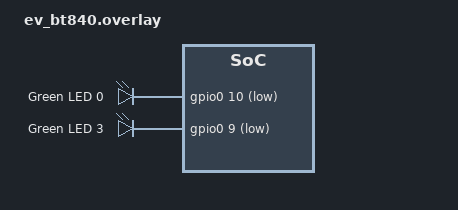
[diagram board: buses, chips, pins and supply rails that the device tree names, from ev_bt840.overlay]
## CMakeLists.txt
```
cmake_minimum_required(VERSION 3.20.0)

add_compile_options(-fdiagnostics-color=always)
add_compile_options(-Wall)
#add_compile_options(-Werror)

find_package(Zephyr REQUIRED HINTS $ENV{ZEPHYR_BASE})
project(radio_rx)

target_sources(app PRIVATE src/main.c src/rx_uart.c src/rx_radio.c src/common/radio.c)
```

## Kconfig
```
source "Kconfig.zephyr"

menu "Serial Radio: Receiver"

config RADIO_RX_APP_LOG_LEVEL
	int "Log level for the radio_rx"
	default 4

endmenu
```

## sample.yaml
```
sample:
  description: Serial Radio Receiver
  name: radio_rx
common:
    tags: introduction
    integration_platforms:
      - native_posix
    harness: console
    harness_config:
      type: one_line
      regex:
        - "Hello World! (.*)"
tests:
  sample.basic.helloworld:
    tags: introduction
```

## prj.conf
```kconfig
CONFIG_DEBUG_THREAD_INFO=n
CONFIG_DEBUG_OPTIMIZATIONS=n

CONFIG_GPIO=y
CONFIG_NFCT_PINS_AS_GPIOS=y

CONFIG_LOG=n
CONFIG_CONSOLE=n

CONFIG_SERIAL=y
CONFIG_UART_ASYNC_API=y
CONFIG_UART_0_NRF_HW_ASYNC=y
# TIMER2 is apparently used by the ESB library.
CONFIG_UART_0_NRF_HW_ASYNC_TIMER=1
CONFIG_UART_1_NRF_HW_ASYNC=y
# TIMER2 is apparently used by the ESB library.
CONFIG_UART_1_NRF_HW_ASYNC_TIMER=3

CONFIG_ESB=y
CONFIG_ESB_TX_FIFO_SIZE=1
CONFIG_ESB_RX_FIFO_SIZE=2
CONFIG_ESB_MAX_PAYLOAD_LENGTH=252

CONFIG_RING_BUFFER=y

CONFIG_MPSL=y
CONFIG_MPSL_FEM_ONLY=y
```

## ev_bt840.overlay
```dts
/ {
	leds {
		compatible = "gpio-leds";
		led0: led_0 {
			gpios = <&gpio0 10 GPIO_ACTIVE_LOW>;
			label = "Green LED 0";
		};
		led3: led_3 {
			gpios = <&gpio0 9 GPIO_ACTIVE_LOW>;
			label = "Green LED 3";
		};
	};
};
```

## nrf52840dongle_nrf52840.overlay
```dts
// To get started, press Ctrl+Space to bring up the completion menu and view the available nodes.

// You can also use the buttons in the sidebar to perform actions on nodes.
// Actions currently available include:

// * Enabling / disabling the node
// * Adding the bus to a bus
// * Removing the node
// * Connecting ADC channels

// For more help, browse the DeviceTree documentation at https://docs.zephyrproject.org/latest/guides/dts/index.html
// You can also visit the nRF DeviceTree extension documentation at https://nrfconnect.github.io/vscode-nrf-connect/devicetree/nrfdevicetree.html

&pinctrl {
	uart0_default: uart0_default {
		group1 {
			psels = <NRF_PSEL(UART_TX, 0, 20)>;
		};
		group2 {
			psels = <NRF_PSEL(UART_RX, 0, 22)>;
			bias-pull-up;
		};
	};

	uart0_sleep: uart0_sleep {
		group1 {
			psels = <NRF_PSEL(UART_TX, 0, 20)>,
				<NRF_PSEL(UART_RX, 0, 22)>;
			low-power-enable;
		};
	};

	uart1_default: uart1_default {
		group1 {
			psels = <NRF_PSEL(UART_TX, 0, 15)>;
		};
		group2 {
			psels = <NRF_PSEL(UART_RX, 0, 17)>;
			bias-pull-up;
		};
	};

	uart1_sleep: uart1_sleep {
		group1 {
			psels = <NRF_PSEL(UART_TX, 0, 15)>,
				<NRF_PSEL(UART_RX, 0, 17)>;
			low-power-enable;
		};
	};
};

&uart1 {
	compatible = "nordic,nrf-uarte";
	status = "okay";
	current-speed = <115200>;
	pinctrl-0 = <&uart1_default>;
	pinctrl-1 = <&uart1_sleep>;
	pinctrl-names = "default", "sleep";
};
```

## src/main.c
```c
#include <esb.h>
#include <zephyr/drivers/uart.h>
#include <zephyr/logging/log.h>
#include <zephyr/sys/ring_buffer.h>

LOG_MODULE_REGISTER(radio_tx, CONFIG_RADIO_TX_APP_LOG_LEVEL);

#include "common/leds.h"
#include "common/radio.h"
#include "rx_radio.h"
#include "rx_uart.h"

// Application defines
#define NUM_CHANNEL RADIO_NUM_PIPES
#define PIPE_BUF_LEN 512

// Thread defines
#define THREAD_NUM 3
#define THREAD_STACK_SIZE 512
#define THREAD_RADIO_PRIORITY 10
#define THREAD_UART_PRIORITY 20
#define THREAD_MAIN_PRIORITY 30

typedef struct {
  const char *name;
  struct k_thread *thread_data;
  k_thread_stack_t *stack;
  size_t stack_size;
  k_thread_entry_t entry;
  void *entry_arg1;
  void *entry_arg2;
  void *entry_arg3;
  int priority;
  uint32_t options;
  k_timeout_t delay;
} ThreadConfig;

// Static state for threads and application.
static uint8_t g_pipe_bufs[NUM_CHANNEL][PIPE_BUF_LEN];
static LitePipe g_pipes[NUM_CHANNEL];

static UartTxState g_uart_states[NUM_CHANNEL];

K_THREAD_STACK_ARRAY_DEFINE(g_thread_stacks, THREAD_NUM, THREAD_STACK_SIZE);
static struct k_thread g_thread_data[THREAD_NUM];

static void InitPipes(void) {
  for (int i = 0; i < NUM_CHANNEL; ++i) {
    LitePipeInit(&g_pipes[i], g_pipe_bufs[i], sizeof(g_pipe_bufs[i]));
  }
}

void main(void) {
  LOG_INF("Starting RX radio...");

  if (SetupLeds() < 0) {
    return;
  };

  InitPipes();

  const UartTxConfig uart_configs[NUM_CHANNEL] = {
      {
          .uart = DEVICE_DT_GET(DT_NODELABEL(uart0)),
          .baud = 921600,
          .pipe = &g_pipes[0],
      },
      {
          .uart = DEVICE_DT_GET(DT_NODELABEL(uart1)),
          .baud = 921600,
          .pipe = &g_pipes[1],
      },
  };

  const RadioRxConfig radio_config = {.pipes = {&g_pipes[0], &g_pipes[1]}};

  k_tid_t threads[THREAD_NUM];
  const ThreadConfig thread_configs[THREAD_NUM] = {
      {
          .name = "RadioRx",
          .thread_data = &g_thread_data[0],
          .stack = g_thread_stacks[0],
          .stack_size = K_THREAD_STACK_SIZEOF(g_thread_stacks[0]),
          .entry = (k_thread_entry_t)RadioRxThread,
          .entry_arg1 = (void *)&radio_config,
          .entry_arg2 = NULL,
          .entry_arg3 = NULL,
          .priority = THREAD_RADIO_PRIORITY,
          .options = 0,
          .delay = K_NO_WAIT,
      },
      {
          .name = "Uart0",
          .thread_data = &g_thread_data[1],
          .stack = g_thread_stacks[1],
          .stack_size = K_THREAD_STACK_SIZEOF(g_thread_stacks[1]),
          .entry = (k_thread_entry_t)UartTxThread,
          .entry_arg1 = (void *)&uart_configs[0],
          .entry_arg2 = &g_uart_states[0],
          .entry_arg3 = NULL,
          .priority = THREAD_UART_PRIORITY + 0,
          .options = 0,
          .delay = K_NO_WAIT,
      },
      {
          .name = "Uart1",
          .thread_data = &g_thread_data[2],
          .stack = g_thread_stacks[2],
          .stack_size = K_THREAD_STACK_SIZEOF(g_thread_stacks[2]),
          .entry = (k_thread_entry_t)UartTxThread,
          .entry_arg1 = (void *)&uart_configs[1],
          .entry_arg2 = &g_uart_states[1],
          .entry_arg3 = NULL,
          .priority = THREAD_UART_PRIORITY + 1,
          .options = 0,
          .delay = K_NO_WAIT,
      },
  };

  for (int i = 0; i < THREAD_NUM; ++i) {
    const ThreadConfig *const c = &thread_configs[i];
    threads[i] = k_thread_create(c->thread_data, c->stack, c->stack_size, c->entry, c->entry_arg1,
                                 c->entry_arg2, c->entry_arg3, c->priority, c->options, c->delay);
    k_thread_name_set(threads[i], c->name);
  }

  // Set priority to background allowing other threads to start.
  k_thread_priority_set(k_current_get(), THREAD_MAIN_PRIORITY);

  bool running_led = false;
  while (true) {
    k_msleep(500);

    // Toggle running LED.
    running_led = !running_led;
    SetLed(LED_RUNNING, running_led);

    // Set error LED based on state of threads.
    bool error_status = false;
    error_status = error_status || RadioRxGetErrorStatus();
    error_status = error_status || UartTxGetErrorStatus(&g_uart_states[0]);
    error_status = error_status || UartTxGetErrorStatus(&g_uart_states[1]);

    SetLed(LED_ERROR, error_status);

    // If any threads exit, toggle error LED indefinitely.
    for (int i = 0; i < THREAD_NUM; ++i) {
      int ret = k_thread_join(thread_configs[i].thread_data, K_NO_WAIT);
      while (ret == 0) {
        SetLed(LED_ERROR, true);
        k_msleep(500);
        SetLed(LED_ERROR, false);
        k_msleep(500);
      }
    }
  }
}
```

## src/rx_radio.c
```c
#include "rx_radio.h"

#include <string.h>

#include <esb.h>
#include <zephyr/kernel.h>
#include <zephyr/logging/log.h>
#include <zephyr/sys/ring_buffer.h>

LOG_MODULE_REGISTER(rx_radio, CONFIG_LOG_LEVEL_DEFAULT);

#include "common/leds.h"
#include "common/lite_pipe.h"
#include "common/radio.h"

typedef struct {
  struct {
    atomic_t pipe_overflow[RADIO_NUM_PIPES];
    atomic_t other;
  } errors;
  atomic_t rx_packets;
  atomic_t rx_bytes[RADIO_NUM_PIPES];
} RadioStats;

typedef struct {
  struct k_sem rx_sem;
  struct esb_payload rx_payload;
  RadioStats stats;
} RadioRxState;

static RadioRxState g_radio_state;

static void EsbHandler(const struct esb_evt *event) {
  switch (event->evt_id) {
    case ESB_EVENT_RX_RECEIVED:
      atomic_inc(&g_radio_state.stats.rx_packets);
      SetLed(LED_RADIO_STATUS, true);
      k_sem_give(&g_radio_state.rx_sem);
      break;
    case ESB_EVENT_TX_SUCCESS:
    case ESB_EVENT_TX_FAILED:
      atomic_inc(&g_radio_state.stats.errors.other);
      break;
  }
}

static int RadioInit(void) {
  k_sem_init(&g_radio_state.rx_sem, 0, 1);
  memset(&g_radio_state.stats, 0, sizeof(g_radio_state.stats));

  if (SetupEsb(ESB_MODE_PRX, EsbHandler) < 0) return -1;

  if (esb_start_rx() < 0) {
    LOG_ERR("Could not start ESB receiving.");
    return -1;
  }

  return 0;
}

bool RadioRxGetErrorStatus(void) {
  bool status = false;

  for (int i = 0; i < RADIO_NUM_PIPES; ++i) {
    status = status || atomic_get(&g_radio_state.stats.errors.pipe_overflow[i]); 
  }

  status = status || atomic_get(&g_radio_state.stats.errors.other);

  return status;
}

void RadioRxThread(const RadioRxConfig *config, void *arg2, void *arg3) {
  if (RadioInit() < 0) return;

  while (true) {
    // Wait for RX data from radio.
    if (k_sem_take(&g_radio_state.rx_sem, K_FOREVER) < 0) {
      atomic_inc(&g_radio_state.stats.errors.other);
      continue;
    }

    // Continually move data from RX FIFO to appropriate ring buffer.
    while (true) {
      int ret = esb_read_rx_payload(&g_radio_state.rx_payload);
      if (ret < 0) {
        if (ret != -ENODATA) {
          atomic_inc(&g_radio_state.stats.errors.other);
        }
        break;
      }

      // Ignore if pipe is out of bounds.
      const uint8_t pipe_num = g_radio_state.rx_payload.pipe;
      if (pipe_num >= RADIO_NUM_PIPES) {
        atomic_inc(&g_radio_state.stats.errors.other);
        continue;
      }

      LitePipe *const pipe = config->pipes[pipe_num];
      uint8_t *const data = g_radio_state.rx_payload.data;
      const size_t len = g_radio_state.rx_payload.length;

      // Flush pipe if not enough room to write RX payload.
      if (LitePipePutAvailable(pipe) < len) {
        atomic_inc(&g_radio_state.stats.errors.pipe_overflow[pipe_num]);

        if (LitePipeFlush(pipe, K_FOREVER) < 0) {
          atomic_inc(&g_radio_state.stats.errors.other);
        }
      }

      // Write RX payload to pipe.
      const size_t bytes_written = LitePipePut(pipe, data, len);
      if (bytes_written != len) {
        atomic_inc(&g_radio_state.stats.errors.other);
      }

      atomic_add(&g_radio_state.stats.rx_bytes[pipe_num], bytes_written);
    }
  }
}
```

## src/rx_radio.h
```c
#pragma once

#include "common/lite_pipe.h"
#include "common/radio.h"

typedef struct {
  LitePipe *pipes[RADIO_NUM_PIPES];
} RadioRxConfig;

void RadioRxThread(const RadioRxConfig *config, void *arg2, void *arg3);
bool RadioRxGetErrorStatus(void);
```

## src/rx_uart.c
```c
#include "rx_uart.h"

#include <string.h>

#include <zephyr/drivers/uart.h>
#include <zephyr/logging/log.h>
#include <zephyr/kernel.h>

LOG_MODULE_REGISTER(rx_uart, CONFIG_LOG_LEVEL_DEFAULT);

#include "common/leds.h"
#include "common/lite_pipe.h"

static void UartCallback(const struct device *uart, struct uart_event *event, UartTxState *state) {
  switch (event->type) {
    case UART_TX_ABORTED:
      atomic_inc(&state->stats.errors.other);
    case UART_TX_DONE:
      atomic_add(&state->stats.tx_bytes, event->data.tx.len);

      SetLed(LED_RADIO_STATUS, false);

      if (k_sem_count_get(&state->tx_done_sem) != 0) {
        atomic_inc(&state->stats.errors.tx_multiple_callbacks);
      }
      k_sem_give(&state->tx_done_sem);
      break;
    case UART_RX_BUF_REQUEST:
    case UART_RX_RDY:
    case UART_RX_DISABLED:
    case UART_RX_STOPPED:
    case UART_RX_BUF_RELEASED:
      atomic_inc(&state->stats.errors.other);
      break;
  }
}

static int UartInit(const UartTxConfig *config, UartTxState *state) {
  int ret;
  if ((ret = k_sem_init(&state->tx_done_sem, 1, 1)) < 0) return ret;
  state->buf_write_index = 0;
  memset(&state->stats, 0, sizeof(state->stats));

  const struct uart_config uart_config = {
      .baudrate = config->baud,
      .parity = UART_CFG_PARITY_NONE,
      .stop_bits = UART_CFG_STOP_BITS_1,
      .data_bits = UART_CFG_DATA_BITS_8,
      .flow_ctrl = UART_CFG_FLOW_CTRL_NONE,
  };

  if (!device_is_ready(config->uart)) {
    LOG_ERR("Could not get uart.");
    return -1;
  }

  if (uart_configure(config->uart, &uart_config) < 0) {
    LOG_ERR("Could not configure uart.");
    return -1;
  }

  if (uart_callback_set(config->uart, (uart_callback_t)UartCallback, state) < 0) {
    LOG_ERR("Could not set uart callback.");
    return -1;
  }

  return 0;
}

bool UartTxGetErrorStatus(const UartTxState *state) {
  bool status = false;
  status = status || atomic_get(&state->stats.errors.tx_multiple_callbacks);
  status = status || atomic_get(&state->stats.errors.other);

  return status;
}

void UartTxThread(const UartTxConfig *config, UartTxState *state, void *arg3) {
  if (UartInit(config, state) < 0) return;

  while (true) {
    // Wait for data from pipe.
    size_t bytes_read = 0;
    int ret = LitePipeGet(config->pipe, state->buf[state->buf_write_index], UART_BUF_LEN,
                          &bytes_read, K_FOREVER);
    if (ret < 0) {
      // Timeout can occur even with K_FOREVER in the case of the producer flushing the pipe.
      if (ret != -EAGAIN) {
        atomic_inc(&state->stats.errors.other);
      }
      continue;
    }

    // Wait until UART is ready for next buffer.
    if (k_sem_take(&state->tx_done_sem, K_FOREVER) < 0) {
      atomic_inc(&state->stats.errors.other);
      continue;
    }

    // Update write buffer.
    const uint32_t read_index = state->buf_write_index;
    if (++state->buf_write_index >= UART_NUM_BUF) state->buf_write_index = 0;

    // Start UART transfer.
    if (uart_tx(config->uart, state->buf[read_index], bytes_read, SYS_FOREVER_US) < 0) {
      atomic_inc(&state->stats.errors.other);
      continue;
    }
  }
}
```

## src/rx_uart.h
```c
#pragma once

#include <zephyr/kernel.h>

#include "common/lite_pipe.h"
#include "common/radio.h"

#define UART_BUF_LEN RADIO_MAX_PKT_LEN
#define UART_NUM_BUF 2

typedef struct {
  const struct device *uart;
  uint32_t baud;
  LitePipe *pipe;
} UartTxConfig;

typedef struct {
  struct {
    atomic_t tx_multiple_callbacks;
    atomic_t other;
  } errors;
  atomic_t tx_bytes;
} UartTxStats;

typedef struct {
  struct k_sem tx_done_sem;
  uint8_t buf[UART_NUM_BUF][UART_BUF_LEN];
  uint32_t buf_write_index;
  UartTxStats stats;
} UartTxState;

void UartTxThread(const UartTxConfig *config, UartTxState *state, void *arg3);
bool UartTxGetErrorStatus(const UartTxState *state);
```
